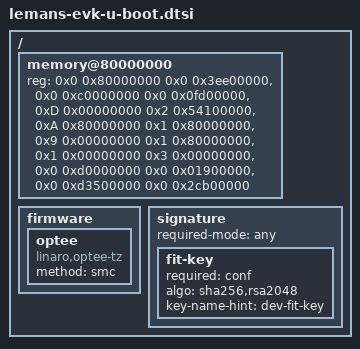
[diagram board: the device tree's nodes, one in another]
// SPDX-License-Identifier: BSD-3-Clause
/*
 * Copyright (c) 2026, Qualcomm Innovation Center, Inc. All rights reserved.
 */

/ {
	/* Will be removed when bootloader updates later */
	memory@80000000 {
		device_type = "memory";
		reg = <0x0 0x80000000 0x0 0x3ee00000>,
		      <0x0 0xc0000000 0x0 0x0fd00000>,
		      <0xD 0x00000000 0x2 0x54100000>,
		      <0xA 0x80000000 0x1 0x80000000>,
		      <0x9 0x00000000 0x1 0x80000000>,
		      <0x1 0x00000000 0x3 0x00000000>,
		      <0x0 0xd0000000 0x0 0x01900000>,
		      <0x0 0xd3500000 0x0 0x2cb00000>;
	};
};

/ {
	/*
	 * OP-TEE runs in the secure world of these boards: U-Boot reaches it
	 * through this node, and copies it to the kernel's device tree, with the
	 * reserved-memory nodes named optee* OP-TEE added for its own memory.
	 */
	firmware {
		optee {
			compatible = "linaro,optee-tz";
			method = "smc";
		};
	};

	signature {
		required-mode = "any";
		fit-key {
			required = "conf";
			algo = "sha256,rsa2048";
			key-name-hint = "dev-fit-key";
#include "u-boot-fit-pubkey.dtsi"
		};
	};
};
